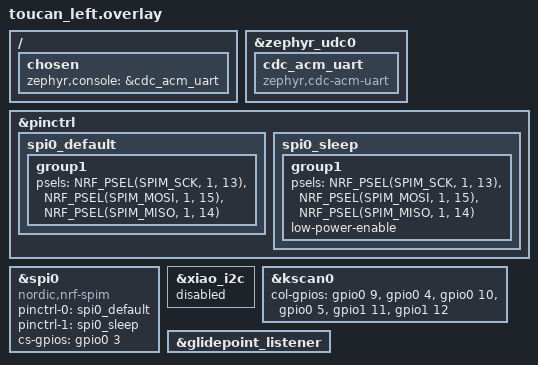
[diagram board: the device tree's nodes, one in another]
#include "toucan.dtsi"

/* CDC ACM UART node + chosen console redirect — always declared. The
 * CDC ACM driver itself is only compiled in when CONFIG_ZMK_USB_LOGGING=y
 * (pulled in by the diagnostics block in config/toucan.conf). In production
 * builds the chosen redirect is harmless: with no CDC ACM driver, kernel
 * logging just has nowhere to go. */
/ {
    chosen {
        zephyr,console = &cdc_acm_uart;
    };
};

&zephyr_udc0 {
    cdc_acm_uart: cdc_acm_uart {
        compatible = "zephyr,cdc-acm-uart";
    };
};

&pinctrl {
    spi0_default: spi0_default {
        group1 {
            psels = <NRF_PSEL(SPIM_SCK, 1, 13)>,
                <NRF_PSEL(SPIM_MOSI, 1, 15)>,
                <NRF_PSEL(SPIM_MISO, 1, 14)>;
        };
    };

     spi0_sleep: spi0_sleep {
        group1 {
            psels = <NRF_PSEL(SPIM_SCK, 1, 13)>,
                    <NRF_PSEL(SPIM_MOSI, 1, 15)>,
                    <NRF_PSEL(SPIM_MISO, 1, 14)>;
            low-power-enable;
        };
    };

};

nice_view_spi: &spi0 {
   compatible = "nordic,nrf-spim";
   pinctrl-0 = <&spi0_default>;
   pinctrl-1 = <&spi0_sleep>;
   pinctrl-names = "default", "sleep";
   cs-gpios = <&gpio0 3 GPIO_ACTIVE_HIGH>;
};

&xiao_i2c {
    status = "disabled";
};

&kscan0 {
    col-gpios
    = <&gpio0 9 GPIO_ACTIVE_HIGH>
    , <&gpio0 4 GPIO_ACTIVE_HIGH>
    , <&gpio0 10 GPIO_ACTIVE_HIGH>
    , <&gpio0 5 GPIO_ACTIVE_HIGH>
    , <&gpio1 11 GPIO_ACTIVE_HIGH>
    , <&gpio1 12 GPIO_ACTIVE_HIGH>
    ;
};

&glidepoint_listener {
    status = "okay";
};
